# ADC1_0.0 register map
Vendor: Texas Instruments
Registers are 32-bit, read-write, no defined reset value unless marked. A register's access mark holds for its fields unless they carry their own. Offsets are as the file gives them; [hi:lo] are bit positions; {n}, {i} and the like mark numbered series.

## ADC1 (part 2 of 2)
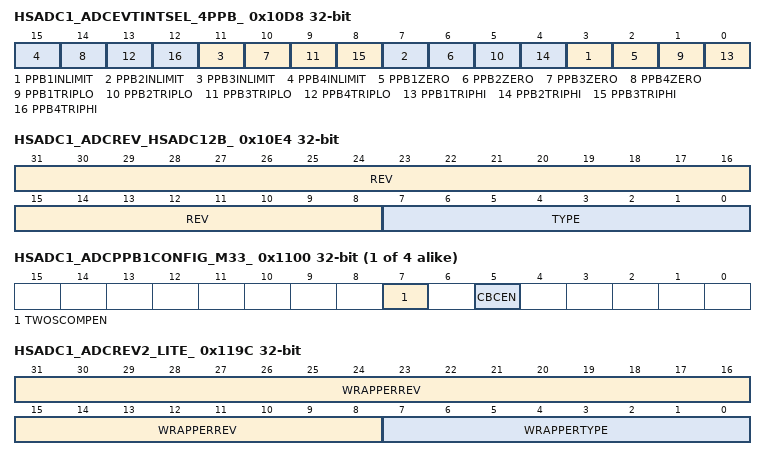
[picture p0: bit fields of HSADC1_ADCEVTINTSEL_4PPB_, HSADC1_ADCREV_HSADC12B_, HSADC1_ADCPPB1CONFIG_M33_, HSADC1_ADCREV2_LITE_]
0x10D8 HSADC1_ADCEVTINTSEL_4PPB_ — ADC Event Interrupt Selection Register
  [4n-1] PPB{n}INLIMIT (n=1..4) — Post Processing Block {n} Within trip limit Interrupt Enable. Setting this bit allows the corresponding rising zero crossing flag to activate the event interrupt signal to the PIE. The flag must be cleared before it can produce additional interrupts to the PIE.
  [4n-2] PPB{n}ZERO (n=1..4) — Post Processing Block {n} Zero Crossing Interrupt Enable. Setting this bit allows the corresponding rising zero crossing flag to activate the event interrupt signal to the PIE. The flag must be cleared before it can produce additional interrupts to the PIE.
  [4n-3] PPB{n}TRIPLO (n=1..4) — Post Processing Block {n} Trip Low Interrupt Enable. Setting this bit allows the corresponding rising trip low flag to activate the event interrupt signal to the PIE. The flag must be cleared before it can produce additional interrupts to the PIE.
  [4n-4] PPB{n}TRIPHI (n=1..4) — Post Processing Block {n} Trip High Interrupt Enable. Setting this bit allows the corresponding rising trip high flag to activate the event interrupt signal to the PIE. The flag must be cleared before it can produce additional interrupts to the PIE.
0x10DC HSADC1_ADCOSDETECT_HSADC12B_ — ADC Open and Shorts Detect Register
  [2:0] DETECTCFG — ADC Opens and Shorts Detect Configuration. This bit field defines the open/shorts detection circuit state. #br# #br# 0h Open/Shorts detection circuit is disabled. #br# 1h Open/Shorts detection circuit is enabled at zero scale. #br# 2h Open/Shorts detection circuit is enabled at full scale. #br# 3h Open/Shorts detection circuit is enabled at (nominal) 5/12 scale. #br# 4h Open/Shorts detection circuit is enabled at (nominal) 7/12 scale. #br# 5h Open/Shorts detection circuit is enabled with a (nominal) 5K pulldown to VSSA. #br# 6h Open/Shorts detection circuit is enabled with a (nominal) 5K pullup to VDDA. #br# 7h Open/Shorts detection circuit is enabled with a (nominal) 7K pulldown to VSSA.
0x10E4 HSADC1_ADCREV_HSADC12B_ ro — ADC Revision Register
  [31:8] REV — ADC Revision. To allow documentation of differences between revisions. First version is labeled as 00h.
  [7:0] TYPE — ADC Type. Always set to 6 for this HSADC-12b.
0x10E8 HSADC1_ADCOFFTRIM_LITE_ — ADC Offset Trim Register 1
  [7:0] OFFTRIM — ADC Offset Trim #br# #br#Adjusts the conversion results of the converter up #br#or down to account for offset error in the ADC. A factory trim setting will be loaded during device boot. #br# #br#Offset can be corrected in the range of +7 to -8 LSBs. Value is 16*Offset in 8-bit 2's complement: #br# #br#7 LSB (16*7) = 112 #br#6 LSB (16*6) = 96 #br#5 LSB (16*5) = 80 #br#4 LSB (16*4) = 64 #br#3 LSB (16*3) = 48 #br#2 LSB (16*2) = 32 #br#1 LSB (16*1) = 16 #br#0 LSB (16*0) = 0 #br#-1 LSB (16*(-1)) = 240 #br#: #br#: #br#-7LSB(16*(-7)) = 144
0x10F0 HSADC1_ADCCONFIG_12B_ access not given — ADC Config Register
{0x10E0+0x20*i} HSADC1_ADCPPB{i}CONFIG_M33_ (i=1..4) — ADC PPB{i} Config Register
  [7] TWOSCOMPEN — ADC Post Processing Block {i} Two's Complement Enable. When set this bit enables the post conversion hardware processing circuit that performs a two's complement on the output of the offset/reference subtraction unit before storing the result in the ADCPPB{i}RESULT register. #br# #br# 0 ADCPPB{i}RESULT = ADCRESULTx - ADCPPB{i}OFFREF #br# 1 ADCPPB{i}RESULT = ADCPPB{i}OFFREF - ADCRESULTx
  [5] CBCEN — ADC Post Processing Block Cycle By Cycle Enable. When set, this bit enables the post conversion hardware processing circuit to automatically clear the ADCEVTSTAT on a conversion if the event condition is no longer present.
{0x10E8+0x20*i} HSADC1_ADCPPB{i}OFFCAL_LITE_ (i=1..4) — ADC PPB{i} Offset Calibration Register
  [5:0] OFFCAL — ADC Post Processing Block {i} Offset Correction. This bit field can be used to digitally remove any system level offset inherent in the ADCIN circuit. This 6-bit signed value is subtracted from the ADC output before being stored in the ADCRESULT register. #br# #br# 00h No change. The ADC output is stored directly into ADCRESULT. #br# 01h ADC output - 1 is stored into ADCRESULT. #br# 02h ADC output - 2 is stored into ADCRESULT. #br# ... #br# 20h ADC output + 32 is stored into ADCRESULT. #br# ... #br# 3Fh ADC output + 1 is stored into ADCRESULT. #br# #br#NOTE: The subtraction will saturate at 0000h and 0FFFh before being stored into the ADCRESULT register. #br# #br#Note: in the case that multiple PPBs point to the same SOC, only the OFFCAL of the lowest numbered PPB will be applied.
{0x10EC+0x20*i} HSADC1_ADCPPB{i}OFFREF_LITE_ (i=1..4) — ADC PPB{i} Offset Reference Register
  [11:0] OFFREF — ADC Post Processing Block {i} Offset Correction. This bit field can be used to either calculate the feedback error or convert a unipolar signal to bipolar by subtracting a reference value. This 12-bit unsigned value is subtracted from the ADCRESULT register before being passed through an optional two's complement function and stored in the ADCPPB{i}RESULT register. This subtraction is not saturated. #br# #br# 0000h No change. The ADCRESULT value is passed on. #br# 001h ADCRESULT - 1 is passed on. #br# 002h ADCRESULT - 2 is passed on. #br# ... #br# 800h ADCRESULT - 2048 is passed on. #br# ... #br# FFFh ADCRESULT - 4096 is passed on.
{0x10F0+0x20*i} HSADC1_ADCPPB{i}TRIPHI_LITE_ (i=1..4) — ADC PPB{i} Trip High Register
  [15:0] LIMITHI — ADC Post Processing Block {i} Trip High Limit. This value sets the digital comparator trip high limit. #br# #br#When comparing to an ADCPPBxRESULT register, the upper bits will be ignored: #br#- TRIPHI[15:13] will be ignored
{0x10F4+0x20*i} HSADC1_ADCPPB{i}TRIPLO_LITE_ (i=1..4) — ADC PPB{i} Trip Low/Trigger Time Stamp Register
  [15:0] LIMITLO — ADC Post Processing Block {i} Trip High Low Limit. This value sets the digital comparator trip low limit if ADCPPB{i}TRIPLO.LIMITLO2EN = 1. #br# #br#When comparing to an ADCPPBxRESULT register, the upper bits will be ignored: #br#- TRIPLO[15:13] will be ignored in 12 bit mode
0x1180 HSADC1_ADCINTCYCLE_LITE_ — ADC Early Interrupt Generation Cycle
  [5:0] DELAY — ADC Early Interrupt Generation Cycle Delay: Defines the delay from the fall edge of ADCSOC in terms of system clock cycles, for the interrupt to be generated.
{0x1180+4i} HSADC1_ADCINLTRIM{i}_TYPE3P1_ access not given (i=1..6) — ADC Linearity Trim {i} Register
0x119C HSADC1_ADCREV2_LITE_ ro — ADC Wrapper Revision Register
  [31:8] WRAPPERREV — ADC Revision. To allow documentation of differences between revisions. First version is labeled as 00h.
  [7:0] WRAPPERTYPE — ADC Wrapper Type. Always set to 6 for this ADC.
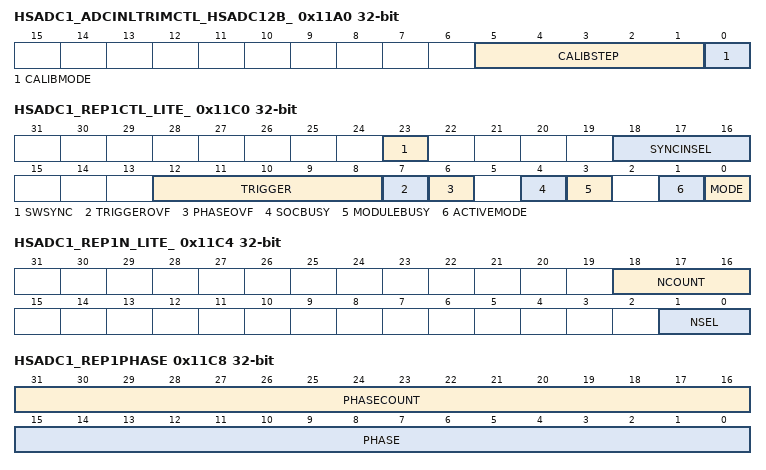
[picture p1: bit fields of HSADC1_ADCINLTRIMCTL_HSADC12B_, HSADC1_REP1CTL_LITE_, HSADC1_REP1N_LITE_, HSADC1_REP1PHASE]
0x11A0 HSADC1_ADCINLTRIMCTL_HSADC12B_ — ADC Linearity Trim Control Register
  [5:1] CALIBSTEP — ADC Linearity Calibration Step. Defines which of the 18 steps of calibration is to be executed.
  [0] CALIBMODE — ADC Linearity Calibration Mode.
0x11C0 HSADC1_REP1CTL_LITE_ access per field — ADC Trigger Repeater 1 Control Register
  [23] SWSYNC rw — Trigger repeater 1 software force sync. On a sync. event, all registers in repeater 1 are reset to a ready and waiting state. Values of NSEL, PHASE, and MODE are preserved. #br# #br#Note: SOCs associated with repeater 1 are not cleared.
  [18:16] SYNCINSEL rw — Trigger repeater 1 sync. input select. On a sync. event, all registers in repeater 1 are reset to a ready and waiting state. Values of NSEL, PHASE, and MODE are preserved. #br# #br#Note: SOCs associated with repeater 1 are not cleared. #br# #br#0h = Disable Syncin to Repeater 1 #br#1h - 1Fh = Hardware syncin sources
  [12:8] TRIGGER rw — ADC Trigger Repeater 1 Trigger Select. Selects the trigger to modify via oversampling or undersampling. #br# #br# 00h REPTRIG0 - Software only #br# 01h-1FH Hardware triggers
  [7] TRIGGEROVF rw — ADC Trigger Repeater 1 Oversampled Trigger Overflow. #br# #br#Indicates that a trigger was dropped because a trigger arrived while the repeater was still generating repeated oversampled triggers (NCOUNT was not 0 or SOCs associated with Repeater 1 were still pending). #br# #br#Writing a 1 will clear this flag. #br# #br#Note: This flag won't be set in undersampling mode or when NSEL = 0; if a trigger arrives before the previous SOCs have completed, the trigger will be passed and the overflow flags of the SOCs that were still pending will be set. #br# #br#Note: If software sets the clear bit on the same cycle that hardware is trying to set the flag bit, then hardware has priority and the overflow bit will remain set.
  [6] PHASEOVF rw — ADC Trigger Repeater 1 Phase Delay Overflow. #br# #br#Indicates that a trigger was dropped because a trigger arrived when the phase delay logic was still waiting to send the delayed trigger (PHASECOUNT was not 0). #br# #br#Writing a 1 will clear this flag. #br# #br#Note: If software sets the clear bit on the same cycle that hardware is trying to set the flag bit, then hardware has priority and the overflow bit will not be set
  [4] SOCBUSY ro — ADC Trigger Repeater 1 Associated SOCs Busy indicator. In oversampling mode: #br# #br#0 = no SOCs associated with this repeater are pending #br#1 = SOCs associated with this repeater are still pending #br# #br#The next repeated trigger to the ADC in oversampling mode will not occur until SPREADCOUNT is 0 (minimum time is complete) and REP1CTL.BUSY = 0 (SOCs associated with trigger repeater 1 are no longer pending). #br# #br#Note: If the ADC is in burstmode and the BURSTTRIG is Repeater 1, then all round-robin SOCs are considered associated with this repeater and the repeater will not re-trigger until there are no pending round-robin SOCs (in addition to any associated pending high-priority SOCs).
  [3] MODULEBUSY ro — ADC Trigger Repeater 1 Module Busy indicator. In oversampling mode: #br# #br#0 = Repeater 1 is idle and can accept a new repeated trigger in oversampling mode #br#1 = Repeater 1 still has repeated triggers remaining (NCOUNT > 0) or associated SOCs are still pending (SOCBUSY is 1) #br# #br#If a new oversampled trigger is received while the module is still busy, the TRIGGEROVF bit will be set and the trigger will be ignored.
  [1] ACTIVEMODE ro — When a trigger is recived in oversampling or undersampling mode the value of MODE is copied to ACTIVEMODE. ACTIVEMODE determines if the repeater will repeat of filter triggers. Changes to MODE while the repeater is working therefore won't cause any changes in functionality until the module becomes idle and then a new trigger is received. #br# #br#0 = module is oversampling #br#1 = module is undersampling
  [0] MODE rw — ADC trigger repeater 1 mode selection. Select either oversampling or undersampling mode. #br# #br#In oversampling mode, when the trigger selected by REP1CTL.TRIGSEL is received, the repeater will repeat the trigger REP1N.NSEL + 1 times. #br# #br#In undersampling mode, when the trigger selected by REP1CTL.TRIGSEL is received the first time, the repeater will pass the trigger through. The next REP1N.NSEL triggers will be ignored. #br# #br#0 = oversampling #br#1 = undersampling
0x11C4 HSADC1_REP1N_LITE_ access per field — ADC Trigger Repeater 1 N Select Register
  [18:16] NCOUNT ro — ADC trigger repeater 1 trigger count. #br# #br#Indicates the number of triggers remaining to be generated. If a trigger is received corresponding to REP1CTL.TRIGSEL while NCOUNT is not 0 (the repeater is still busy generating the repeated triggers) then the trigger will be ignored and REP1CTL.TRIGOVF will be set to 1.
  [1:0] NSEL rw — ADC Trigger Repeater 1 selection of number of triggers. #br# #br#In oversampling mode, selects the number of repeated triggers. For each trigger received corresponding to REP1CTL.TRIGSEL, 2^NSEL triggers will be generated. #br# #br#0 = 1 trigger is generated (pass-through) #br#1 = 2 triggers are generated #br#2 = 4 triggers are generated #br#3 = 8 triggers are generated #br# #br#In undersampling mode, selects the number triggers to be supressed. 1 out NSEL + 1 triggers received corresponding to REP1CTL.TRIGSEL will be passed through (the first trigger will be passed through and the subsequent NSEL triggers will be supressed). #br# #br#0 = all triggers are passed #br#1 = 1 out of 2 triggers are passed #br#2 = 1 out of 3 triggers are passed #br#... #br#127 = 1 out of 128 triggers are passed
0x11C8 HSADC1_REP1PHASE access per field — ADC Trigger Repeater 1 Phase Select Register
  [31:16] PHASECOUNT ro — ADC trigger repeater 1 phase delay status. When the trigger selected by REP1CTL.TRIGSEL is received, this register will start counting down from PHASECOUNT until the counter reaches 0, at which point the trigger will be passed on to the repeater re-trigger logic. #br# #br#If the trigger selected by REP1CTL.TRIGSEL is recieved when PHASECOUNT is not 0 (the phase delay logic is busy from the previous trigger) then the new trigger will be ignored and REP1CTL.PHASEOVF will be set to 1.
  [15:0] PHASE rw — ADC trigger repeater 1 phase delay configuration. Defines the number of SYSCLKs to delay the selected trigger before passing it on to the re-triggering logic. #br# #br#0 = trigger is passed through without delay #br#1 = trigger is delayed by 1 SYSCLK #br#2 = trigger is delayed by 2 SYSCLKs #br#... #br#65535 = trigger is delayed by 65535 SYSCLKs
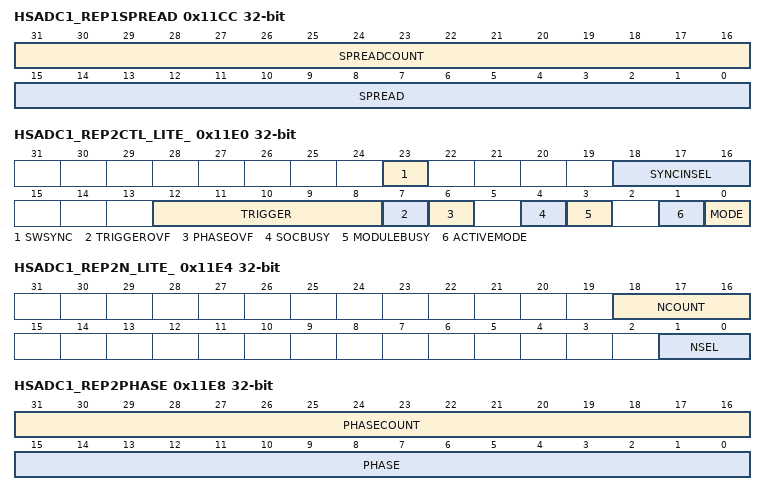
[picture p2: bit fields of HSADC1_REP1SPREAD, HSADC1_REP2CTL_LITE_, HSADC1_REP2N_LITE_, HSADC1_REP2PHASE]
0x11CC HSADC1_REP1SPREAD access per field — ADC Trigger Repeater 1 Spread Select Register
  [31:16] SPREADCOUNT ro — ADC trigger repeater 1 spread status. When a trigger is sent to the ADC in oversampling mode, this register will start counting down from SPREAD until SPREADCOUNT equals 0. #br# #br#The next repeated trigger to the ADC in oversampling mode will not occur until SPREADCOUNT is 0 (minimum time is complete) and REP1CTL.BUSY = 0 (SOCs associated with trigger repeater 1 are no longer pending).
  [15:0] SPREAD rw — ADC trigger repeater 1 spread delay configuration. In oversampling mode, defines the minimum number of SYSCLKs to wait before creating the next repeated trigger to the ADC. #br# #br#If SPREAD is less than the time needed for all SOCs associated with repeater 1 to sample and convert, then the repeater will generate triggers as fast as the ADC can convert the associated conversions. #br# #br#If SPREAD is greater than the time needed for all SOCs associated with repeater 1 to sample and convert, then repeated triggers to the ADC will be SPREAD SYSCLK cycles apart. #br# #br#0 = oversampled repeated triggers occur as fast as the ADC can sample and convert associated SOCs #br#1 = time between repeated triggers is at least 1 SYSCLKs #br#2 = time between repeated triggers is at least 2 SYSCLKs #br#... #br#65535 = time between repeated triggers is at least 65535 SYSCLKs
0x11D0 HSADC1_REP1FRC_LITE_ — ADC Trigger Repeater 1 Software Force Register
  [0] SWFRC — Write 1 to force a trigger to repeat block 1 input regardless of the value of TRIGGER. #br# #br#Always reads 0.
0x11E0 HSADC1_REP2CTL_LITE_ access per field — ADC Trigger Repeater 2 Control Register
  [23] SWSYNC rw — Trigger repeater 2 software force sync. On a sync. event, all registers in repeater 2 are reset to a ready and waiting state. Values of NSEL, PHASE, and MODE are preserved. #br# #br#Note: SOCs associated with repeater 2 are not cleared.
  [18:16] SYNCINSEL rw — Trigger repeater 2 sync. input select. On a sync. event, all registers in repeater 2 are reset to a ready and waiting state. Values of NSEL, PHASE, and MODE are preserved. #br# #br#Note: SOCs associated with repeater 2 are not cleared. #br# #br#0h = Disable Syncin to Repeater 2 #br#1h - 1Fh = Hardware syncin sources
  [12:8] TRIGGER rw — ADC Trigger Repeater 2 Trigger Select. Selects the trigger to modify via oversampling or undersampling. #br# #br# 00h REPTRIG0 - Software only #br# 01h-1FH Hardware triggers
  [7] TRIGGEROVF rw — ADC Trigger Repeater 2 Oversampled Trigger Overflow. #br# #br#Indicates that a trigger was dropped because a trigger arrived while the repeater was still generating repeated oversampled triggers (NCOUNT was not 0 or SOCs associated with Repeater 2 were still pending). #br# #br#Writing a 1 will clear this flag. #br# #br#Note: This flag won't be set in undersampling mode or when NSEL = 0; if a trigger arrives before the previous SOCs have completed, the trigger will be passed and the overflow flags of the SOCs that were still pending will be set. #br# #br#Note: If software sets the clear bit on the same cycle that hardware is trying to set the flag bit, then hardware has priority and the overflow bit will remain set.
  [6] PHASEOVF rw — ADC Trigger Repeater 2 Phase Delay Overflow. #br# #br#Indicates that a trigger was dropped because a trigger arrived when the phase delay logic was still waiting to send the delayed trigger (PHASECOUNT was not 0). #br# #br#Writing a 1 will clear this flag. #br# #br#Note: If software sets the clear bit on the same cycle that hardware is trying to set the flag bit, then hardware has priority and the overflow bit will not be set
  [4] SOCBUSY ro — ADC Trigger Repeater 2 Associated SOCs Busy indicator. In oversampling mode: #br# #br#0 = no SOCs associated with this repeater are pending #br#1 = SOCs associated with this repeater are still pending #br# #br#The next repeated trigger to the ADC in oversampling mode will not occur until SPREADCOUNT is 0 (minimum time is complete) and REP2CTL.BUSY = 0 (SOCs associated with trigger repeater 2 are no longer pending). #br# #br#Note: If the ADC is in burstmode and the BURSTTRIG is Repeater 2, then all round-robin SOCs are considered associated with this repeater and the repeater will not re-trigger until there are no pending round-robin SOCs (in addition to any associated pending high-priority SOCs).
  [3] MODULEBUSY ro — ADC Trigger Repeater 2 Module Busy indicator. In oversampling mode: #br# #br#0 = Repeater 2 is idle and can accept a new repeated trigger in oversampling mode #br#1 = Repeater 2 still has repeated triggers remaining (NCOUNT > 0) or associated SOCs are still pending (SOCBUSY is 1) #br# #br#If a new oversampled trigger is received while the module is still busy, the TRIGGEROVF bit will be set and the trigger will be ignored.
  [1] ACTIVEMODE ro — When a trigger is recived in oversampling or undersampling mode the value of MODE is copied to ACTIVEMODE. ACTIVEMODE determines if the repeater will repeat of filter triggers. Changes to MODE while the repeater is working therefore won't cause any changes in functionality until the module becomes idle and then a new trigger is received. #br# #br#0 = module is oversampling #br#1 = module is undersampling
  [0] MODE rw — ADC trigger repeater 2 mode selection. Select either oversampling or undersampling mode. #br# #br#In oversampling mode, when the trigger selected by REP2CTL.TRIGSEL is received, the repeater will repeat the trigger REP2N.NSEL + 1 times. #br# #br#In undersampling mode, when the trigger selected by REP2CTL.TRIGSEL is received the first time, the repeater will pass the trigger through. The next REP2N.NSEL triggers will be ignored. #br# #br#0 = oversampling #br#1 = undersampling
0x11E4 HSADC1_REP2N_LITE_ access per field — ADC Trigger Repeater 2 N Select Register
  [18:16] NCOUNT ro — ADC trigger repeater 2 trigger count. #br# #br#Indicates the number of triggers remaining to be generated. If a trigger is received corresponding to REP2CTL.TRIGSEL while NCOUNT is not 0 (the repeater is still busy generating the repeated triggers) then the trigger will be ignored and REP2CTL.TRIGOVF will be set to 1.
  [1:0] NSEL rw — ADC Trigger Repeater 2 selection of number of triggers. #br# #br#In oversampling mode, selects the number of repeated triggers. For each trigger received corresponding to REP2CTL.TRIGSEL, 2^NSEL triggers will be generated. #br# #br#0 = 1 trigger is generated (pass-through) #br#1 = 2 triggers are generated #br#2 = 4 triggers are generated #br#3 = 8 triggers are generated #br# #br#In undersampling mode, selects the number triggers to be supressed. 1 out NSEL + 1 triggers received corresponding to REP2CTL.TRIGSEL will be passed through (the first trigger will be passed through and the subsequent NSEL triggers will be supressed). #br# #br#0 = all triggers are passed #br#1 = 1 out of 2 triggers are passed #br#2 = 1 out of 3 triggers are passed #br#... #br#127 = 1 out of 128 triggers are passed
0x11E8 HSADC1_REP2PHASE access per field — ADC Trigger Repeater 2 Phase Select Register
  [31:16] PHASECOUNT ro — ADC trigger repeater 2 phase delay status. When the trigger selected by REP2CTL.TRIGSEL is received, this register will start counting down from PHASECOUNT until the counter reaches 0, at which point the trigger will be passed on to the repeater re-trigger logic. #br# #br#If the trigger selected by REP2CTL.TRIGSEL is recieved when PHASECOUNT is not 0 (the phase delay logic is busy from the previous trigger) then the new trigger will be ignored and REP2CTL.PHASEOVF will be set to 1.
  [15:0] PHASE rw — ADC trigger repeater 2 phase delay configuration. Defines the number of SYSCLKs to delay the selected trigger before passing it on to the re-triggering logic. #br# #br#0 = trigger is passed through without delay #br#1 = trigger is delayed by 1 SYSCLK #br#2 = trigger is delayed by 2 SYSCLKs #br#... #br#65535 = trigger is delayed by 65535 SYSCLKs
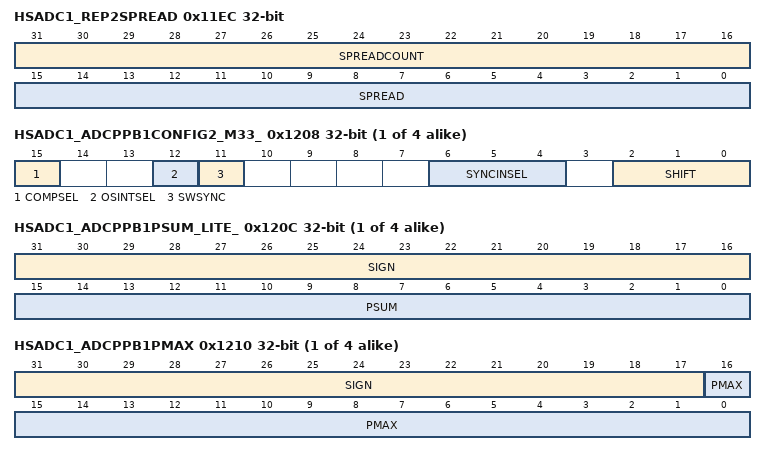
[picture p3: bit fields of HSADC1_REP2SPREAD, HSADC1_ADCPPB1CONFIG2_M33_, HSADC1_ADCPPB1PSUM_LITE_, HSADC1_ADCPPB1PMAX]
0x11EC HSADC1_REP2SPREAD access per field — ADC Trigger Repeater 2 Spread Select Register
  [31:16] SPREADCOUNT ro — ADC trigger repeater 2 spread status. When a trigger is sent to the ADC in oversampling mode, this register will start counting down from SPREAD until SPREADCOUNT equals 0. #br# #br#The next repeated trigger to the ADC in oversampling mode will not occur until SPREADCOUNT is 0 (minimum time is complete) and REP2CTL.BUSY = 0 (SOCs associated with trigger repeater 2 are no longer pending).
  [15:0] SPREAD rw — ADC trigger repeater 2 spread delay configuration. In oversampling mode, defines the minimum number of SYSCLKs to wait before creating the next repeated trigger to the ADC. #br# #br#If SPREAD is less than the time needed for all SOCs associated with repeater 2 to sample and convert, then the repeater will generate triggers as fast as the ADC can convert the associated conversions. #br# #br#If SPREAD is greater than the time needed for all SOCs associated with repeater 2 to sample and convert, then repeated triggers to the ADC will be SPREAD SYSCLK cycles apart. #br# #br#0 = oversampled repeated triggers occur as fast as the ADC can sample and convert associated SOCs #br#1 = time between repeated triggers is at least 1 SYSCLKs #br#2 = time between repeated triggers is at least 2 SYSCLKs #br#... #br#65535 = time between repeated triggers is at least 65535 SYSCLKs
0x11F0 HSADC1_REP2FRC_LITE_ — ADC Trigger Repeater 2 Software Force Register
  [0] SWFRC — Write 1 to force a trigger to repeat block 2 input regardless of the value of TRIGGER. #br# #br#Always reads 0.
{0x11C0+0x40*i} HSADC1_ADCPPB{i}LIMIT_LITE_ (i=1..4) — ADC PPB{i}Conversion Count Limit Register
  [1:0] LIMIT — Post Processing Block {i} Oversampling Limit. Defines the number of conversions to accumulate before PSUM is automatically loaded into SUM. #br# #br#0 = No - accumulation #br#1 = 2 conversions are accumulated #br#2 = 4 conversions are accumulated #br#3 = 8 conversions are accumulated #br#
{0x11C4+0x40*i} HSADC1_ADCPPB{i}PCOUNT_LITE_ ro (i=1..4) — ADC PPB{i} Partial Conversion Count Register
  [2:0] PCOUNT — Post Processing Block {i} Oversampling Partial Count. Each time a new result propagates through the PPB signal chain and accumulates into ADCPPB{i}PSUM this register is incremented by 1. #br# #br#This register is reset when either a count-match event occurs (PCOUNT = LIMIT) or PPB{i} receives a sync. event. #br# #br#This result is available 1 SYSCLK cycle after the associated ADCPPB{i}RESULT is available. This will be 2 SYSCLK cycles after the associated ADCRESULT is available, unless multiple PPBs point to the same SOC (refer to the ADCPPB{i}RESULT timing information).
{0x11C8+0x40*i} HSADC1_ADCPPB{i}CONFIG2_M33_ (i=1..4) — ADC PPB{i} Sum Shift Register
  [15] COMPSEL — Post Processing Block {i} Compare Source Select. This field determines whether ADCPPB{i}RESULT or ADCPPB{i}SUM is used for the threshold compare. #br# #br#0 = ADCPPB{i}RESULT is used for compare logic #br#1 = ADCPPB{i}SUM is used for compare logic
  [12] OSINTSEL — Post Processing Block {i} Interrupt Source Select. #br# #br#OSINT{i} can be used to trigger an ADC interrupt (ADCINT1 through ADCINT4) via selection in the ADCINT1N2 or ADCINT3N4. This selection determines if a sync. event can trigger OSINT{i} in addition to a PCOUNT = LIMIT event. #br# #br#0 = OSINT{i} will be generated from PCOUNT = LIMIT only #br#1 = OSTIN{i} will be generated form PCOUNT = LIMIT or a sync. event. #br# #br#Note: If a SYNC event would cause an OSINT one cycle after OSINT would have been cause by PCOUNT = LIMIT match, then the second OSINT is ignored.
  [11] SWSYNC — PPB {i} software force sync. On a sync. event, all partial registers transfer to the final registers and are then reset. #br# #br#Note: In the case where the software force occurs at the same time that a new sample is added to the PSUM and the PSUM is being used for a high or low limit compare, then the comparison will not occur.
  [6:4] SYNCINSEL — PPB {i} sync. input select. On a sync. event, all partial registers transfer to the final registers and are then reset. #br#Refer to SOC spec for details
  [2:0] SHIFT — Post Processing Block {i} right shift. Defines the number of bits to right shift PSUM before loading into the final SUM. #br# #br#0 : no right shift #br#1 : SUM = PSUM >> 1 #br#2 : SUM = PSUM >> 2 #br#... #br#7 : SUM = PSUM >> 7
{0x11CC+0x40*i} HSADC1_ADCPPB{i}PSUM_LITE_ ro (i=1..4) — ADC PPB{i} Partial Sum Register
  [31:16] SIGN — Sign Extended Bits. These bits reflect the same value as bit 15.
  [15:0] PSUM — Post Processing Block {i} Oversampling Partial Sum. Each time a new result propagates through the PPB signal chain and latches into ADCPPB{i}RESULT the result is subsequently accumulated into this register. #br# #br#This register is reset when either a count-match event occurs (PCOUNT = LIMIT) or PPB{i} receives a sync. event. #br# #br#This result is available 1 SYSCLK cycle after the associated ADCPPB{i}RESULT is available. This will be 2 SYSCLK cycles after the associated ADCRESULT is available, unless multiple PPBs point to the same SOC. In the case of multiple PPBs associated with the same SOC, the lowest numbered PPB's result will be availble 2 SYSCLK cycle after the associated ADCRESULT and subsequent results (in order from lowest numbered PPB to highest) will each become available every 2-3 SYSCLK cycles (refer to the TRM for detailed timing information).
{0x11D0+0x40*i} HSADC1_ADCPPB{i}PMAX ro (i=1..4) — ADC PPB{i} Partial Max Register
  [31:17] SIGN — Sign Extended Bits. These bits reflect the same value as bit 16.
  [16:0] PMAX — Post Processing Block {i} Oversampling Partial Max. Each time a new result propagates through the PPB signal chain and latches into ADCPPB{i}RESULT the result replaces this register if it is larger. #br# #br#This register is reset when either a count-match event occurs (PCOUNT = LIMIT) or PPB{i} receives a sync. event. #br# #br#This result is available 1 SYSCLK cycle after the associated ADCPPB{i}RESULT is available. This will be 2 SYSCLK cycles after the associated ADCRESULT is available, unless multiple PPBs point to the same SOC (refer to the ADCPPB{i}RESULT timing information).
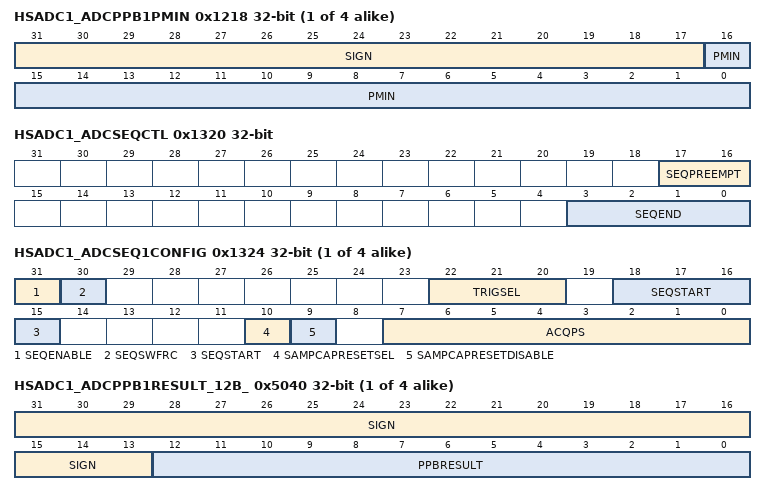
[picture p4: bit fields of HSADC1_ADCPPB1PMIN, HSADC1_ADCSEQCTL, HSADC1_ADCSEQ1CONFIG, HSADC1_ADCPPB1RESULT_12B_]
{0x11D8+0x40*i} HSADC1_ADCPPB{i}PMIN ro (i=1..4) — ADC PPB{i} Partial MIN Register
  [31:17] SIGN — Sign Extended Bits. These bits reflect the same value as bit 16.
  [16:0] PMIN — Post Processing Block {i} Oversampling Partial Min. Each time a new result propagates through the PPB signal chain and latches into ADCPPB{i}RESULT the result replaces this register if it is smaller. #br# #br#This register is reset when either a count-match event occurs (PCOUNT = LIMIT) or PPB{i} receives a sync. event. #br# #br#This result is available 1 SYSCLK cycle after the associated ADCPPB{i}RESULT is available. This will be 2 SYSCLK cycles after the associated ADCRESULT is available, unless multiple PPBs point to the same SOC (refer to the ADCPPB{i}RESULT timing information).
{0x11E0+0x40*i} HSADC1_ADCPPB{i}TRIPLO2 (i=1..4) — ADC PPB{i} Extended Trip Low Register
  [23:0] LIMITLO — ADC Post Processing Block {i} Trip High Low Limit. This value sets the digital comparator trip low limit if ADCPPB{i}TRIPLO.LIMITLO2EN = 1. #br# #br#When comparing to an ADCPPBxRESULT register, the upper bits will be ignored: #br#- TRIPLO2[23:17] will be ignored in 16 bit mode #br#- TRIPLO2[23:13] will be ignored in 12 bit mode
0x130C HSADC1_DTB_HSADC12B_ ro — Digital Test Bus
  [15:0] DTB_OUT — Digital Test Bus from HSADC12b
0x1320 HSADC1_ADCSEQCTL — ADC Sequencer common control Register
  [17:16] SEQPREEMPT — SoC Sequence PREEMPT #br#0X: Pre-empt disabled #br#10: Pre-empt enabled and will not restart aborted Sequence #br#11: Pre-empt enabled and will restart aborted Sequence
  [3:0] SEQEND — END SOC of last enabled sequence
{0x1320+4i} HSADC1_ADCSEQ{i}CONFIG (i=1..4) — ADC Sequencer {i} Config register
  [31] SEQENABLE — SEQ{i}Enable #br#Indicates whether the Sequence{i} is enabled or not
  [30] SEQSWFRC — Write 1 to force a trigger to Sequencer {i} regardless of the value of Hardware TRIGGER. #br# #br#Always reads 0.
  [22:20] TRIGSEL — SOC{i} Trigger Source Select. Along with the SOC{i} field in the ADCINTSOCSEL1 register, this bit field configures which trigger will set the SOC{i} flag in the ADCSOCFLG1 register to initiate a conversion to start once priority is given to it. #br# #br#Note: SOCFRC1 register can always be used to software trigger SOCs in addition to any hardware trigger configuration. #br# 0h ADCTRIG0 - Software only #br# 1h - 7h Hardware triggers
  [18:15] SEQSTART — Beginning SOC of SEQ{i}
  [10] SAMPCAPRESETSEL — SOC{i} Sample Cap Reset Select : Resets sample cap after conversion to either vrefhi/2 or vreflo #br#0 - The sample cap is reset to Vreflo after each conversion #br#1 - The sample cap is reset to Vrefhi/2 after each conversion
  [9] SAMPCAPRESETDISABLE — SOC{i} Sample Cap Reset enable : Resets sample cap after conversion. #br#0 - The sample cap is reset after each conversion #br#1 - The sample cap is not reset after each conversion
  [7:0] ACQPS — SOC{i} Acquisition Prescale. Controls the sample and hold window for each SOC in this Seqeunce. The configured acquisition time must be at least as long as one ADCCLK cycle for correct ADC operation. The device datasheet will also specify a minimum sample and hold window duration. #br#S+H window values is defined based on a combonation of ACQPS[7:6] and ACQPS[5:0] values #br#If ACQPS[7:6] value is #br# "00" S+H window = ACQPS[5:0] + 1 sysclk cycles #br# "01" S+H window = 64 + ((ACQPS[5:0] +1) * 2) sysclk cycles #br# "10" S+H window = 192 + ((ACQPS[5:0] +1) * 4) sysclk cycles #br# "11" S+H window = 448 + ((ACQPS[5:0] +1) * 16) sysclk cycles
{0x5000+2i} HSADC1_ADCRESULT{i}_12B_M33 16-bit access not given (i=0..15) — ADC Result {i} Register
{0x503C+4i} HSADC1_ADCPPB{i}RESULT_12B_ ro (i=1..4) — ADC Post Processing Block {i} Result Register
  [31:13] SIGN — Sign Extended Bits. These bits reflect the same value as bit 12. #br# #br#NOTE: If the conversion associated with this Post Processing Block is a 12-bit conversion, the SIGN bits extend down to bit 12, and all reflect the same value as bit 12.
  [12:0] PPBRESULT — ADC Post Processing Block Result {i} #br# #br#The result of the offset/reference subtraction post conversion processing is stored in this register. #br# #br#This result is available 1 SYSCLK cycle after the associated ADCRESULT is available, unless multiple PPBs point to the same SOC. In the case of multiple PPBs associated with the same SOC, the lowest numbered PPB's result will be availble 1 SYSCLK cycle after the associated ADCRESULT and subsequent results (in order from lowest numbered PPB to highest) will each become available every 2-3 SYSCLK cycles (refer to the TRM for more detailed timing information). #br# #br#If ADCINTFLG is polled to determine when to read the PPBRESULT, it may be necessary to add one or more NOP instructions to ensure that the updated post conversion processing result has posted to the register. #br# #br#NOTE: If the conversion associated with this Post Processing Block is a 12-bit conversion, the PPBRESULT bits are limited to bits 12:0.
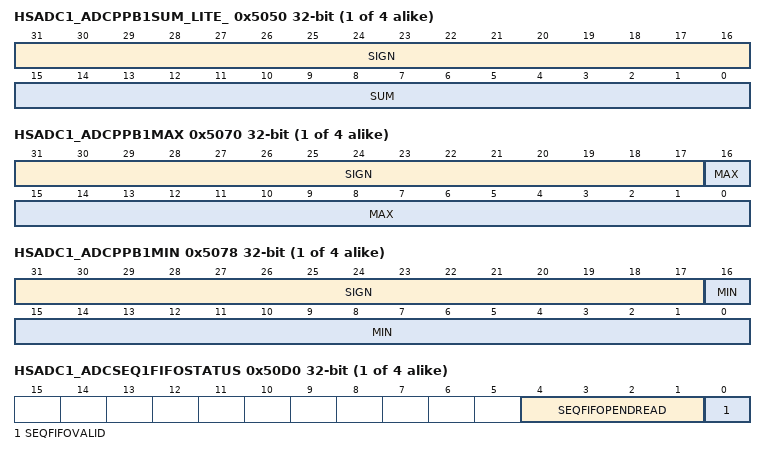
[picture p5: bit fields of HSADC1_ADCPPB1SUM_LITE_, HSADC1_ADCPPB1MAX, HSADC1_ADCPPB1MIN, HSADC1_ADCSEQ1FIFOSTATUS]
{0x5048+8i} HSADC1_ADCPPB{i}SUM_LITE_ ro (i=1..4) — ADC PPB {i} Final Sum Result Register
  [31:16] SIGN — Sign Extended Bits. These bits reflect the same value as bit 15.
  [15:0] SUM — Post Processing Block {i} Oversampling Final Sum. When either a count-match event occurs (PCOUNT = LIMIT) or PPB{i} receives a sync. event, the value of PSUM is loaded into this register. In the case of a count-match event, the sum loaded into this register includes the value from the most recent conversion. #br# #br#The value from PSUM will be right shifted by the amount specified in the SHIFT register before being loaded into the final SUM result register. #br# #br#This result is available 1 SYSCLK cycle after the associated ADCPPB{i}RESULT is available (only in case of a count-match event). This will be 2 SYSCLK cycles after the associated ADCRESULT is available, unless multiple PPBs point to the same SOC (refer to the ADCPPB{i}RESULT timing information).
{0x504C+8i} HSADC1_ADCPPB{i}COUNT_LITE_ 16-bit ro (i=1..4) — ADC PPB{i} Final Conversion Count Register
  [3:0] COUNT — Post Processing Block {i} Oversampling Final Count. When either a count-match event occurs (PCOUNT = LIMIT) or PPB{i} receives a sync. event, the value of PCOUNT is loaded into this register. #br# #br#This result is available 1 SYSCLK cycle after the associated ADCPPB{i}RESULT is available (only in case of a count-match event). This will be 2 SYSCLK cycles after the associated ADCRESULT is available, unless multiple PPBs point to the same SOC (refer to the ADCPPB{i}RESULT timing information).
{0x5060+0x10*i} HSADC1_ADCPPB{i}MAX ro (i=1..4) — ADC PPB {i} Final Max Result Register
  [31:17] SIGN — Sign Extended Bits. These bits reflect the same value as bit 16.
  [16:0] MAX — Post Processing Block {i} Oversampling Final Max. When either a count-match event occurs (PCOUNT = LIMIT) or PPB{i} receives a sync. event, the value of PMAX is loaded into this register. In the case of a count-match event, the max loaded into this register includes the value from the most recent conversion. #br# #br#This result is available 1 SYSCLK cycle after the associated ADCPPB{i}RESULT is available (only when a count-match event occurs). This will be 2 SYSCLK cycles after the associated ADCRESULT is available, unless multiple PPBs point to the same SOC (refer to the ADCPPB{i}RESULT timing information).
{0x5064+0x10*i} HSADC1_ADCPPB{i}MAXI 16-bit ro (i=1..4) — ADC PPB {i} Final Max Index Result Register
  [9:0] MAXI — Post Processing Block {i} Oversampling Final Index of the Max. When either a count-match event occurs (PCOUNT = LIMIT) or PPB{i} receives a sync. event, the value of PMAXI is loaded into this register. In the case of a count-match event, the max index loaded into this register includes the value from the most recent conversion. #br# #br#This result is available 1 SYSCLK cycle after the associated ADCPPB{i}RESULT is available (only in case of a count-match event). This will be 2 SYSCLK cycles after the associated ADCRESULT is available, unless multiple PPBs point to the same SOC (refer to the ADCPPB{i}RESULT timing information).
{0x5068+0x10*i} HSADC1_ADCPPB{i}MIN ro (i=1..4) — ADC PPB {i} Final Min Result Register
  [31:17] SIGN — Sign Extended Bits. These bits reflect the same value as bit 16.
  [16:0] MIN — Post Processing Block {i} Oversampling Final Min. When either a count-match event occurs (PCOUNT = LIMIT) or PPB{i} receives a sync. event, the value of PMIN is loaded into this register. In the case of a count-match event, the max loaded into this register includes the value from the most recent conversion. #br# #br#This result is available 1 SYSCLK cycle after the associated ADCPPB{i}RESULT is available (only in case of a count-match event). This will be 2 SYSCLK cycles after the associated ADCRESULT is available, unless multiple PPBs point to the same SOC (refer to the ADCPPB{i}RESULT timing information).
{0x506C+0x10*i} HSADC1_ADCPPB{i}MINI 16-bit ro (i=1..4) — ADC PPB {i} Final Min Index Result Register
  [9:0] MINI — Post Processing Block {i} Oversampling Final Index of the Min. When either a count-match event occurs (PCOUNT = LIMIT) or PPB{i} receives a sync. event, the value of PMINI is loaded into this register. In the case of a count-match event, the min index loaded into this register includes the value from the most recent conversion. #br# #br#This result is available 1 SYSCLK cycle after the associated ADCPPB{i}RESULT is available (only in case of a count-match event). This will be 2 SYSCLK cycles after the associated ADCRESULT is available, unless multiple PPBs point to the same SOC (refer to the ADCPPB{i}RESULT timing information).
{0x50BC+4i} HSADC1_ADCSEQ{i}FIFORESULT access not given (i=1..4) — ADC Sequence {i} FIFO Result Register
{0x50CC+4i} HSADC1_ADCSEQ{i}FIFOSTATUS ro (i=1..4) — ADC Sequence {i} FIFO Status
  [4:1] SEQFIFOPENDREAD — Sequencer {i} FIFO pending reads #br#Note: #br#1. This field is only updated when after the last byte of ADCSEQ{i}FIFORESULT is read. #br#2. The Pending read information will not be updated for debug reads. #br#3. Once all the data in the FIFO has been read, FIFO will wrap back. Subsequent reads will read from the beginning of the FIFO.
  [0] SEQFIFOVALID — Sequencer {i} FIFO Valid #br#0 - All Conversions associated with the current Sequencer are NOT complete. #br#1 - Conversion from all the SOCs associated with the Sequencer are complete and result is available to be read.
